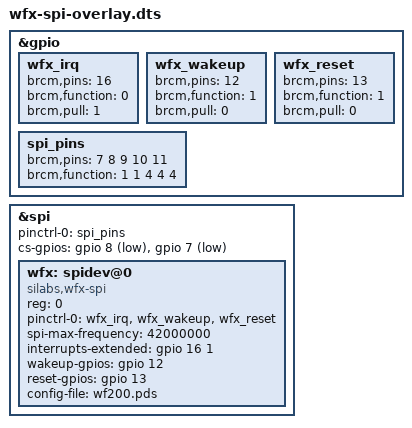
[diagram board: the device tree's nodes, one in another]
/dts-v1/;
/plugin/;

/*
 * In order to allow compilation out of kernel tree, avoid including headers
 * nor define macros in this overlay.
 *
 * Reminder about usefull defines:
 *   - from <dt-bindings/interrupt-controller/irq.h>
 *       #define IRQ_TYPE_EDGE_RISING    1
 *   - from <dt-bindings/gpio/gpio.h>
 *       #define GPIO_ACTIVE_LOW         1
 *       #define GPIO_ACTIVE_HIGH        0
 *   - from <dt-bindings/pinctrl/bcm2835.h>
 *       #define BCM2835_FSEL_GPIO_IN    0
 *       #define BCM2835_FSEL_GPIO_OUT   1
 *       #define BCM2835_FSEL_ALT5       2
 *       #define BCM2835_FSEL_ALT4       3
 *       #define BCM2835_FSEL_ALT0       4
 *       #define BCM2835_FSEL_ALT1       5
 *       #define BCM2835_FSEL_ALT2       6
 *       #define BCM2835_FSEL_ALT3       7
 *
 *       #define BCM2835_PUD_OFF         0
 *       #define BCM2835_PUD_DOWN        1
 *       #define BCM2835_PUD_UP          2
 */

/ {

	fragment@0 {
		target = <&gpio>;
		__overlay__ {
			// Common part with wfx-spi.dtbo
			wfx_irq: wfx_irq {
				brcm,pins = <16>;
				brcm,function = <0>; /* BCM2835_FSEL_GPIO_IN */
				brcm,pull = <1>; /* BCM2835_PUD_DOWN */
			};
			wfx_wakeup: wfx_wakeup {
				brcm,pins = <12>;
				brcm,function = <1>; /* BCM2835_FSEL_GPIO_OUT */
				brcm,pull = <0>; /* BCM2835_PUD_OFF */
			};
			wfx_reset: wfx_reset {
				brcm,pins = <13>;
				brcm,function = <1>; /* BCM2835_FSEL_GPIO_OUT */
				// This pull-up/pull-down configuration is used
				// when device is unbind (indeed, in this case,
				// GPIO function are set to INPUT)
				brcm,pull = <0>; /* BCM2835_PUD_OFF */
			};
			spi_pins: spi_pins {
				brcm,pins = <7 8 9 10 11>;
				brcm,function = <1 1 4 4 4>; /* BCM2835_FSEL_GPIO_OUT / BCM2835_FSEL_ALT0 */
			};
		};
	};

	fragment@1 {
		target = <&spi>;
		__overlay__ {
			status = "okay";
			#address-cells = <1>; /* avoid dtc warning */
			#size-cells = <0>; /* avoid dtc warning */
			pinctrl-names = "default";
			pinctrl-0 = <&spi_pins>;
			cs-gpios = <&gpio 8 1>, <&gpio 7 1>;
			wfx: spidev@0 {
				status = "okay";
				// Append "spidev" to be able to also use spidev driver
				compatible = "silabs,wfx-spi";
				reg = <0>;
				pinctrl-names = "default";
				pinctrl-0 = <&wfx_irq &wfx_wakeup &wfx_reset>;
				spi-max-frequency = <42000000>; // necessary for dtparam
				interrupts-extended = <&gpio 16 1>;
				wakeup-gpios = <&gpio 12 0>;
				reset-gpios = <&gpio 13 0>;
				config-file = "wf200.pds"; // necessary for dtparam
			};
		};
	};

	__overrides__ {
		config_file = <&wfx>,"config-file";
		spi_max_frequency = <&wfx>,"spi-max-frequency:0";
		max_frequency = <&wfx>,"spi-max-frequency:0";
	};
};
